# R7FA6T2BD register map
Vendor: Renesas Electronics Corporation; Series: RA6; File version: 1.40.00
CPU: CM33 r0p4, little endian, MPU, FPU, VTOR, 4 interrupt priority bits, 96 interrupts
Registers are 32-bit, read-write, reset 0x0 unless marked. A register's access mark holds for its fields unless they carry their own. Offsets are from the block's base; [hi:lo] are bit positions; {n}, {i} and the like mark numbered series.

## CPSCU — CPU System Security Control Unit
Base 0x40008000
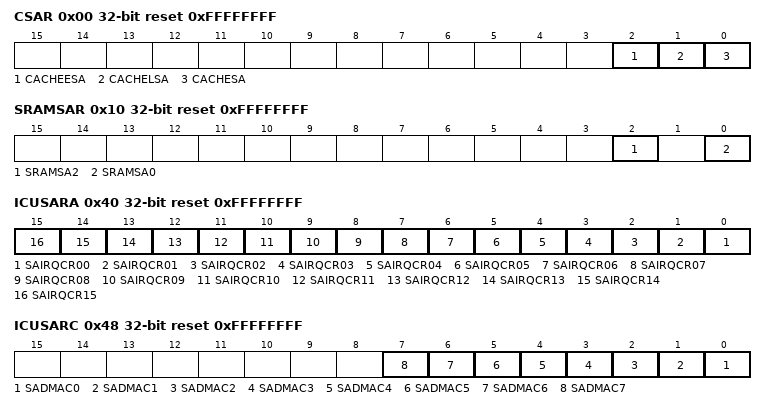
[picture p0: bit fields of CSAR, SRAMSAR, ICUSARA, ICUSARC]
0x00 CSAR reset 0xFFFFFFFF — Cache Security Attribution Register
  [all] fields
    0=Secure; 1=Non-secure
  [2] CACHEESA — Security Attributes of Registers for Cache Error
  [1] CACHELSA — Security Attributes of Registers for Cache Line Configuration
  [0] CACHESA — Security Attributes of Registers for Cache Control
0x10 SRAMSAR reset 0xFFFFFFFF — SRAM Security Attribution Register
  [2] SRAMSA2 — Security attributes of registers for ECC Relation
    0=Secure; 1=Non-Secure
  [0] SRAMSA0 — Security attributes of registers for SRAM Protection
    0=Secure; 1=Non-Secure
0x14 STBRAMSAR reset 0xFFFFFFF0 — Standby RAM memory Security Attribution Register
  [3:0] NSBSTBR — Security attributes of each region for Standby RAM
    0=Region7-0 are all Secure; 1=Region7 is Non-secure. Region6-0 are Secure; 2=Region7-6 are Non-secure. Region5-0 are Secure.; 3=Region7-5 are Non-secure. Region4-0 are Secure.; 4=Region7-4 are Non-secure. Region 3-0 are Secure.; 5=Region7-3 are Non-secure. Region 2-0 are Secure.; 6=Region7-2 are Non-secure. Region 1-0 are Secure.; 7=Region7-1 are Non-Secure. Region0 is Secure.; other=Others (Region7-0 are all Non-Secure.)
0x30 DTCSAR reset 0xFFFFFFFF — DTC Controller Security Attribution Register
  [0] DTCSTSA — DTC Security Attribution
    0=Secure; 1=Non-Secure
0x34 DMACSAR reset 0xFFFFFFFF — DMAC Controller Security Attribution Register
  [0] DMASTSA — DMAST Security Attribution
    0=Secure; 1=Non-secure
0x40 ICUSARA reset 0xFFFFFFFF — Interrupt Controller Unit Security Attribution Register A
  [all] fields
    0=Secure; 1=Non-secure
  [n] SAIRQCR{n:02} (n=0..15) — Security attributes of registers for the IRQCRn register
0x44 ICUSARB reset 0xFFFFFFFF — Interrupt Controller Unit Security Attribution Register B
  [0] SANMI — Security attributes of registers for nonmaskable interrupt
    0=Secure; 1=Non-secure
0x48 ICUSARC reset 0xFFFFFFFF — Interrupt Controller Unit Security Attribution Register C
  [all] fields
    0=Secure; 1=Non-secure
  [n] SADMAC{n} (n=0..7) — Security attributes of registers for DMAC channel
0x4C ICUSARD reset 0xFFFFFFFF — Interrupt Controller Unit Security Attribution Register D
  [0] SASELSR0 — Security attributes of registers for SELSR0
    0=Secure; 1=Non-secure
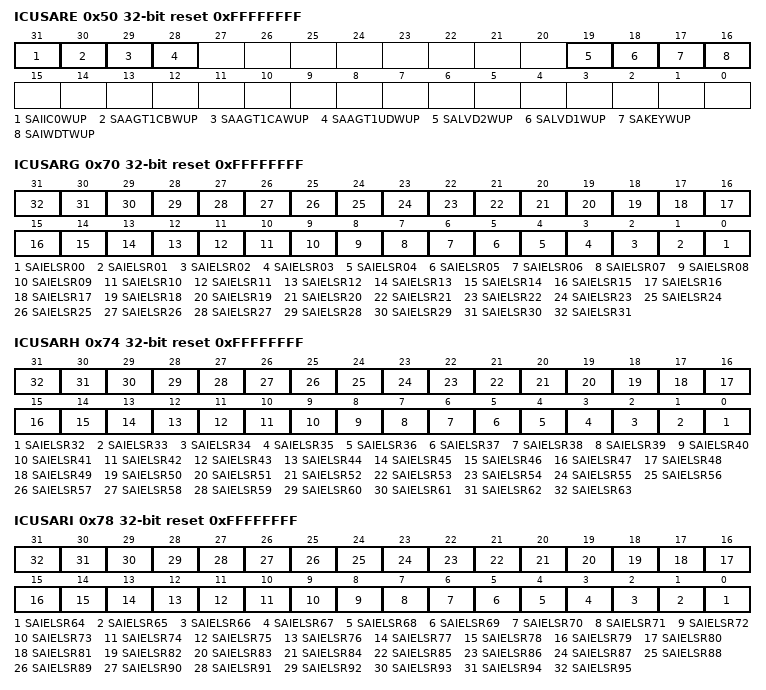
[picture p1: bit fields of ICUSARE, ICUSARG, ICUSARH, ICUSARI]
0x50 ICUSARE reset 0xFFFFFFFF — Interrupt Controller Unit Security Attribution Register E
  [all] fields
    0=Secure; 1=Non-secure
  [31] SAIIC0WUP — Security attributes of registers for WUPEN0.b31
  [30] SAAGT1CBWUP — Security attributes of registers for WUPEN0.b30
  [29] SAAGT1CAWUP — Security attributes of registers for WUPEN0.b29
  [28] SAAGT1UDWUP — Security attributes of registers for WUPEN0.b28
  [19] SALVD2WUP — Security attributes of registers for WUPEN0.b19
  [18] SALVD1WUP — Security attributes of registers for WUPEN0.b18
  [17] SAKEYWUP — Security attributes of registers for WUPEN0.b17
  [16] SAIWDTWUP — Security attributes of registers for WUPEN0.b16
0x70 ICUSARG reset 0xFFFFFFFF — Interrupt Controller Unit Security Attribution Register G
  [all] fields
    0=Secure; 1=Non-secure
  [n] SAIELSR{n:02} (n=0..31) — Security attributes of registers for IELSR31 to IELSR0
0x74 ICUSARH reset 0xFFFFFFFF — Interrupt Controller Unit Security Attribution Register H
  [all] fields
    0=Secure; 1=Non-secure
  [n-32] SAIELSR{n} (n=32..63) — Security attributes of registers for IELSR63 to IELSR32
0x78 ICUSARI reset 0xFFFFFFFF — Interrupt Controller Unit Security Attribution Register I
  [all] fields
    0=Secure; 1=Non-secure
  [n-64] SAIELSR{n} (n=64..95) — Security attributes of registers for IELSR95 to IELSR64
0x100 BUSSARA reset 0xFFFFFFFF — BUS Security Attribution Register A
  [0] BUSSA0 — BUS Security Attribution A0
    0=Secure; 1=Non-Secure
0x104 BUSSARB reset 0xFFFFFFFF — BUS Security Attribution Register B
  [0] BUSSB0 — BUS Security Attribution B0
    0=Secure; 1=Non-Secure
0x130 MMPUSARA reset 0xFFFFFFFF — Master Memory Protection Unit Security Attribution Register A
  [7:0] MMPUASAn — MMPUA Security Attribution (n = 0 to 7)
    0=Secure; 1=Non-Secure
0x134 MMPUSARB reset 0xFFFFFFFF — Master Memory Protection Unit Security Attribution Register B
  [0] MMPUBSA0 — MMPUB Security Attribution
    0=Secure; 1=Non-Secure
0x180 TZFSAR reset 0xFFFFFFFE — TrustZone Filter Security Attribution Register
  [0] TZFSA0 — Security attributes of registers for TrustZone Filter
    0=Secure; 1=Non-secure
0x1B0 CPUDSAR reset 0xFFFFFFFE — CPU Debug Security Attribution Register
  [0] CPUDSA0 — CPU Debug Security Attribution 0
    0=Secure; 1=Non-secure

## Notices in the file
This software is supplied by Renesas Electronics Corporation and is only intended for
use with Renesas products. No other uses are authorized. This software is owned by
Renesas Electronics Corporation and is protected under all applicable laws, including
copyright laws.
THIS SOFTWARE IS PROVIDED "AS IS" AND RENESAS MAKES NO WARRANTIES REGARDING
THIS SOFTWARE, WHETHER EXPRESS, IMPLIED OR STATUTORY, INCLUDING BUT NOT LIMITED TO
WARRANTIES OF MERCHANTABILITY, FITNESS FOR A PARTICULAR PURPOSE AND NON-INFRINGEMENT.
ALL SUCH WARRANTIES ARE EXPRESSLY DISCLAIMED. TO THE MAXIMUM EXTENT PERMITTED NOT
PROHIBITED BY LAW, NEITHER RENESAS ELECTRONICS CORPORATION NOR ANY OF ITS AFFILIATED
COMPANIES SHALL BE LIABLE FOR ANY DIRECT, INDIRECT, SPECIAL, INCIDENTAL OR CONSEQUENTIAL
DAMAGES FOR ANY REASON RELATED TO THIS SOFTWARE, EVEN IF RENESAS OR ITS AFFILIATES HAVE
BEEN ADVISED OF THE POSSIBILITY OF SUCH DAMAGES.
Renesas reserves the right, without notice, to make changes to this software and to
discontinue the availability of this software. By using this software, you agree to
the additional terms and conditions found by accessing the following link:
http://www.renesas.com/disclaimer
